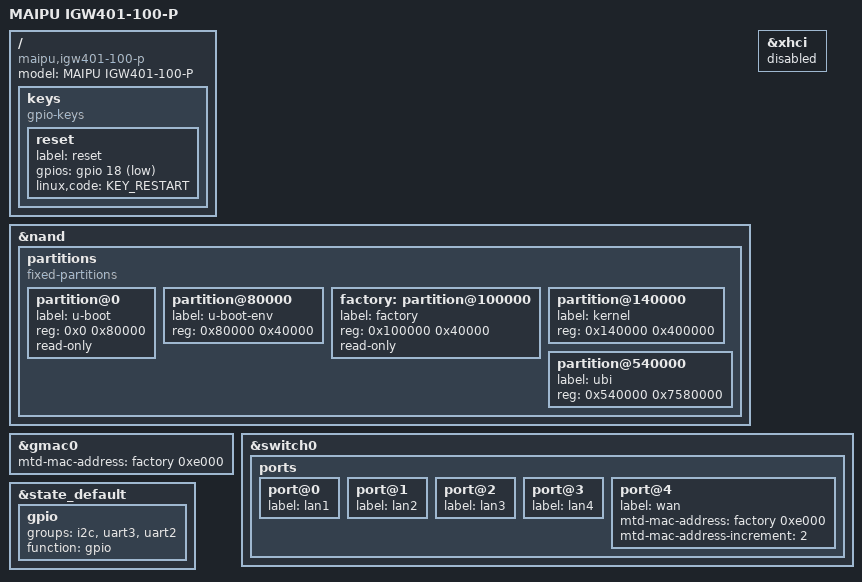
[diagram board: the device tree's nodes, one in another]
// SPDX-License-Identifier: GPL-2.0-only

#include "mt7621.dtsi"

#include <dt-bindings/gpio/gpio.h>
#include <dt-bindings/input/input.h>

/ {
	compatible = "maipu,igw401-100-p", "mediatek,mt7621-soc";
	model = "MAIPU IGW401-100-P";

	keys {
		compatible = "gpio-keys";

		reset {
			label = "reset";
			gpios = <&gpio 18 GPIO_ACTIVE_LOW>;
			linux,code = <KEY_RESTART>;
		};
	};
};

&nand {
	status = "okay";

	partitions {
		compatible = "fixed-partitions";
		#address-cells = <1>;
		#size-cells = <1>;

		partition@0 {
			label = "u-boot";
			reg = <0x0 0x80000>;
			read-only;
		};

		partition@80000 {
			label = "u-boot-env";
			reg = <0x80000 0x40000>;
		};


		factory: partition@100000 {
			label = "factory";
			reg = <0x100000 0x40000>;
			read-only;
		};

		partition@140000 {
			label = "kernel";
			reg = <0x140000 0x400000>;
		};

		partition@540000 {
			label = "ubi";
			reg = <0x540000 0x7580000>;
		};
	};
};

&xhci {
	status = "disabled";
};

&gmac0 {
	mtd-mac-address = <&factory 0xe000>;
};

&switch0 {
	ports {
		port@0 {
			status = "okay";
			label = "lan1";
		};

		port@1 {
			status = "okay";
			label = "lan2";
		};

		port@2 {
			status = "okay";
			label = "lan3";
		};

		port@3 {
			status = "okay";
			label = "lan4";
		};

		port@4 {
			status = "okay";
			label = "wan";
			mtd-mac-address = <&factory 0xe000>;
			mtd-mac-address-increment = <2>;
		};
	};
};

&state_default {
	gpio {
		groups = "i2c", "uart3", "uart2";
		function = "gpio";
	};
};
